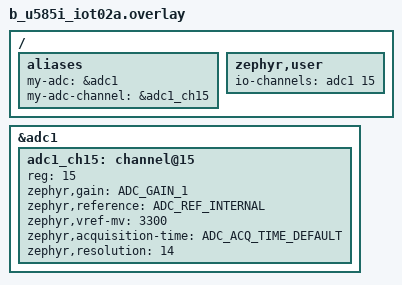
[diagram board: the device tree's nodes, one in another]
/ {
    aliases {
        my-adc = &adc1;
        my-adc-channel = &adc1_ch15;
    };
};

/ {
	zephyr,user {
		/* adjust channel number according to pinmux in board.dts */
		io-channels = <&adc1 15>;
	};
};

&adc1 {
	#address-cells = <1>;
	#size-cells = <0>;

	adc1_ch15: channel@15 { // A5 -> PB0
		reg = <15>;
		zephyr,gain = "ADC_GAIN_1";
		zephyr,reference = "ADC_REF_INTERNAL";
        zephyr,vref-mv = <3300>;
		zephyr,acquisition-time = <ADC_ACQ_TIME_DEFAULT>;
		zephyr,resolution = <14>;
	};
};
